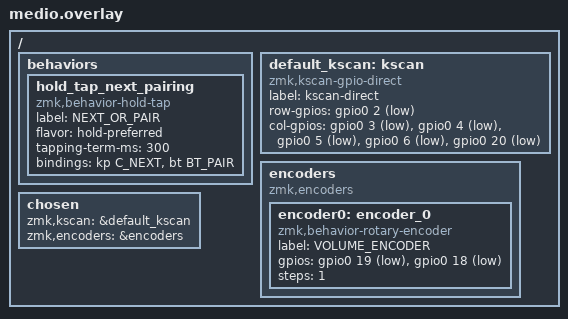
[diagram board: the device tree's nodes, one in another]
#include <behaviors.dtsi>
#include <dt-bindings/zmk/keys.h>
#include <dt-bindings/zmk/bt.h>

/ {
    behaviors {
        hold_tap_next_pairing: hold_tap_next_pairing {
            compatible = "zmk,behavior-hold-tap";
            label = "NEXT_OR_PAIR";
            #binding-cells = <2>;
            flavor = "hold-preferred";
            tapping-term-ms = <300>;
            bindings = <&kp>, <&bt>;
            bindings = <&kp C_NEXT>, <&bt BT_PAIR>;
        };
    };

    default_kscan: kscan {
        compatible = "zmk,kscan-gpio-direct";
        label = "kscan-direct";

        row-gpios = <&gpio0 2 (GPIO_ACTIVE_LOW|GPIO_PULL_UP)>;

        col-gpios = 
            <&gpio0 3 (GPIO_ACTIVE_LOW|GPIO_PULL_UP)>,   // Key 1
            <&gpio0 4 (GPIO_ACTIVE_LOW|GPIO_PULL_UP)>,   // Key 2
            <&gpio0 5 (GPIO_ACTIVE_LOW|GPIO_PULL_UP)>,   // Key 3
            <&gpio0 6 (GPIO_ACTIVE_LOW|GPIO_PULL_UP)>,   // Key 4
            <&gpio0 20 (GPIO_ACTIVE_LOW|GPIO_PULL_UP)>;  // Encoder button
    };

    encoders {
        compatible = "zmk,encoders";
        encoder0: encoder_0 {
            compatible = "zmk,behavior-rotary-encoder";
            label = "VOLUME_ENCODER";
            gpios = <&gpio0 19 (GPIO_ACTIVE_LOW|GPIO_PULL_UP)>,
                    <&gpio0 18 (GPIO_ACTIVE_LOW|GPIO_PULL_UP)>;
            steps = <1>;
            status = "okay";
        };
    };
};

/ {
    chosen {
        zmk,kscan = &default_kscan;
        zmk,encoders = &encoders;
    };
};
